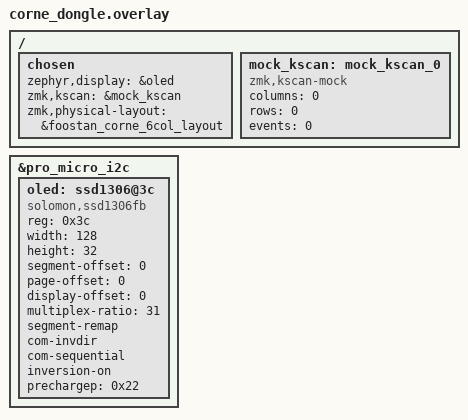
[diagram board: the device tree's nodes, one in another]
#include <dt-bindings/zmk/matrix_transform.h>
#include <layouts/foostan/corne/6column.dtsi>

/ {
    chosen {
        zephyr,display = &oled;
        zmk,kscan = &mock_kscan;
        zmk,physical-layout = &foostan_corne_6col_layout;
    };

    mock_kscan: mock_kscan_0 {
        compatible = "zmk,kscan-mock";
        columns = <0>;
        rows = <0>;
        events = <0>;
    };
};

&pro_micro_i2c {
    status = "okay";

    oled: ssd1306@3c {
        compatible = "solomon,ssd1306fb";
        reg = <0x3c>;
        width = <128>;
        height = <32>;
        segment-offset = <0>;
        page-offset = <0>;
        display-offset = <0>;
        multiplex-ratio = <31>;
        segment-remap;
        com-invdir;
        com-sequential;
        inversion-on;
        prechargep = <0x22>;
    };
};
